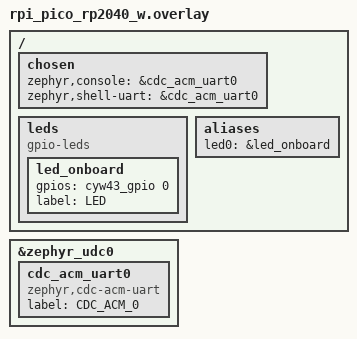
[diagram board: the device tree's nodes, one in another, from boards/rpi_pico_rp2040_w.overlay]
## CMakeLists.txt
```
cmake_minimum_required(VERSION 3.20.0)

find_package(Zephyr REQUIRED)
project(rpi_usb_console)

target_sources(app PRIVATE src/main.cpp)
```

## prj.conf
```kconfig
CONFIG_GPIO=y
CONFIG_LOG=y

# Needed for RPI Pico W
CONFIG_CYW43439=y
CONFIG_NETWORKING=y
CONFIG_WIFI=y
CONFIG_WIFI_AIROC=y
CONFIG_GPIO_CYW43=y
CONFIG_ENTROPY_GENERATOR=y
CONFIG_TEST_RANDOM_GENERATOR=y

# USB Console configuration
CONFIG_USB_DEVICE_STACK=y
CONFIG_USB_CDC_ACM=y
CONFIG_UART_LINE_CTRL=y

CONFIG_SERIAL=y
CONFIG_CONSOLE=y
CONFIG_UART_CONSOLE=y

# Here set to redirect stdout/log to USB CDC
CONFIG_USB_DEVICE_INITIALIZE_AT_BOOT=y
```

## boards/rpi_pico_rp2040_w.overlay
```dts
&zephyr_udc0 {
	cdc_acm_uart0: cdc_acm_uart0 {
		compatible = "zephyr,cdc-acm-uart";
		label = "CDC_ACM_0";
	};
};


/ {
	chosen {
        zephyr,console = &cdc_acm_uart0;
        zephyr,shell-uart = &cdc_acm_uart0;
    };

	leds {
		compatible = "gpio-leds";

		led_onboard: led_onboard {
			gpios = <&cyw43_gpio 0 GPIO_ACTIVE_HIGH>;
			label = "LED";
		};
	};

	aliases {
		led0 = &led_onboard;
	};
};
```

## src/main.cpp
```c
#include <zephyr/drivers/gpio.h>
#include <zephyr/kernel.h>
#include <zephyr/logging/log.h>

#define SLEEP_TIME_MS 1000

/* The devicetree node identifier for the "led0" alias. */
#define LED_NODE DT_ALIAS(led0)

static const struct gpio_dt_spec led = GPIO_DT_SPEC_GET(LED_NODE, gpios);

LOG_MODULE_REGISTER(main, LOG_LEVEL_INF);

int main(void)
{
    bool led_state = true;

    if (!gpio_is_ready_dt(&led)) return 0;

    if (gpio_pin_configure_dt(&led, GPIO_OUTPUT_ACTIVE) < 0) return 0;

    while (1) {
        if (gpio_pin_toggle_dt(&led) < 0) return 0;

        led_state = !led_state;
        LOG_INF("LED state: %s", led_state ? "ON" : "OFF");
        k_msleep(SLEEP_TIME_MS);
    }
    return 0;
}
```
